# ROT_L3Interconnect register map
Vendor: Texas Instruments
Peripheral module from a debugger description file (folder omap4430).
Registers are 32-bit, access per field, reset 0x0 unless marked. A register's access mark holds for its fields unless they carry their own. Offsets are as the file gives them; lines under a group give offsets from that group; [hi:lo] are bit positions; {n}, {i} and the like mark numbered series; 'fields as' and 'values as' point back to an identical list; <NAME> marks a mode.

## ROT_L3Interconnect
0x00 ROT_REVISION ro reset not defined — Module revision
  [31:0] RESERVED — IP Revision
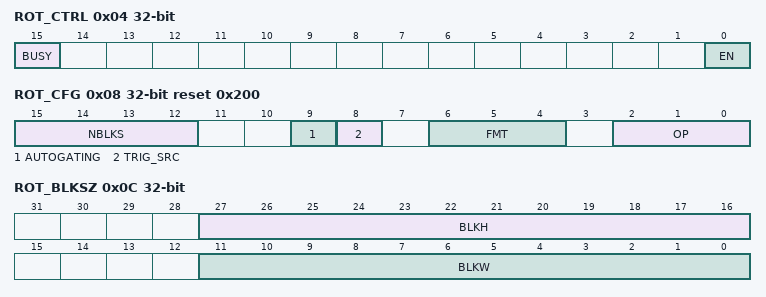
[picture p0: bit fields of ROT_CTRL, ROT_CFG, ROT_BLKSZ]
0x04 ROT_CTRL — Control
  [15] BUSY ro — Idle/busy status (read-only) 0 = Idle, 1 = Busy
  [0] EN wo — Module enable, writing 1 starts the module; always reads as 0.
0x08 ROT_CFG reset 0x200 — Configuration
  [15:12] NBLKS rw — Number of blocks minus 1 0: 1 block, 1: 2 blocks, etc.
  [9] AUTOGATING rw — Internal interconnect and functional clock gating 0: Interconnect and functional clocks are free-running. 1: Automatic clock gating is applied, based on the interface activity for the interface clock, and on the functional activity for the functional clocks.
  [8] TRIG_SRC rw — Trigger source 0 = MMR write 1 = Hardware start signal
  [6:4] FMT rw — Data format 0 = 8-bit data 1 = 16-bit data 2 = 32-bit data 3 = YUV4:2:2 data 4 = YUV4:2:0 data
  [2:0] OP rw — Operation 0 = Rotate 0 degree 1 = Rotate 90 degrees 2 = Rotate 180 degrees 3 = Rotate 270 degrees 4 = Data shift (FMT = 0) 5 = Horizontal circular (FMT = 0) shift
0x0C ROT_BLKSZ — Block size
  [27:16] BLKH rw — Block height, in pixels (YUV4:2:0/4:2:2) or number of rows (8-/16-/32-bit). Should be a multiple of 8, and at least 8, for rotation. Should be at least 1 for data shifting.
  [11:0] BLKW rw — Block width, in pixels (YUV4:2:0/4:2:2) or data units (8-/16-/32-bit). Should be a multiple of 8, and at least 8, for rotation. Should be at least 4 for data shifting.
0x10 ROT_SRC_START1 — Source starting address
  [13:0] ADDR rw — Byte address Should be a multiple of 8 for rotation. No constraint for data shifting.
0x14 ROT_SRC_LOFST — Source line offset
  [15:0] LOFST rw — Line offset in bytes Should be a multiple of 8 for rotation and normal data shifting. Should be a power of 2 and at least 32 for horizontal circular shifting.
0x18 ROT_DST_START1 — Destination starting address
  fields as ROT_SRC_START1
0x1C ROT_DST_LOFST — Destination line offset
  fields as ROT_SRC_LOFST
0x20 ROT_SRC_START2 — Source starting address 2 (only form YUV4:2:0 FMT = 2)
  [13:0] ADDR rw — Byte address, should be a multiple of 8.
0x24 ROT_DST_START2 — Destination starting address 2 (only form YUV4:2:0 FMT = 2)
  [13:0] ADDR rw — Byte address, should be a multiple of 8.
